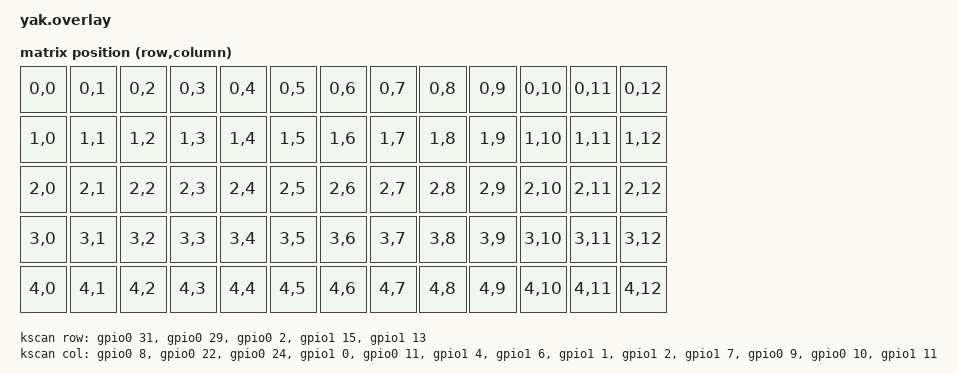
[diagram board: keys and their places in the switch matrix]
// This file was generated from a template. Edit it to match your keyboard.
// See https://zmk.dev/docs/development/hardware-integration/new-shield for more
// instructions.

#include <dt-bindings/zmk/matrix_transform.h>

#include "yak-layouts.dtsi"

&pinctrl {
    spi0_default: spi0_default {
        group1 {
            psels = <NRF_PSEL(SPIM_SCK, 0, 20)>,
                <NRF_PSEL(SPIM_MOSI, 0, 17)>,
                <NRF_PSEL(SPIM_MISO, 0, 25)>;
        };
    };
    spi0_sleep: spi0_sleep {
        group1 {
            psels = <NRF_PSEL(SPIM_SCK, 0, 20)>,
                <NRF_PSEL(SPIM_MOSI, 0, 17)>,
                <NRF_PSEL(SPIM_MISO, 0, 25)>;
            low-power-enable;
        };
    };
};

nice_view_spi: &spi0 {
    compatible = "nordic,nrf-spim";
    pinctrl-0 = <&spi0_default>;
    pinctrl-1 = <&spi0_sleep>;
    pinctrl-names = "default", "sleep";
    cs-gpios = <&pro_micro 6 GPIO_ACTIVE_HIGH>;
};

/ {
    chosen {
        zmk,physical-layout = &default_layout;
    };

    kscan: kscan {
        compatible = "zmk,kscan-gpio-matrix";
        diode-direction = "col2row";
        wakeup-source;

        // Replace these comments with the GPIO pins in the matrix.
        // See https://zmk.dev/docs/development/hardware-integration/new-shield#shield-overlays
        col-gpios
            = <&gpio0 8 GPIO_ACTIVE_HIGH>  /* COL1 -> P0.08 */
            , <&gpio0 22 GPIO_ACTIVE_HIGH>  /* COL2 -> P0.22 */
            , <&gpio0 24 GPIO_ACTIVE_HIGH>  /* COL3 -> P0.24 */
            , <&gpio1 0 GPIO_ACTIVE_HIGH>  /* COL4 -> P1.00 */
            , <&gpio0 11 GPIO_ACTIVE_HIGH>  /* COL5 -> P0.11 */
            , <&gpio1 4 GPIO_ACTIVE_HIGH>  /* COL6 -> P1.04 */
            , <&gpio1 6 GPIO_ACTIVE_HIGH>  /* COL7 -> P1.06 */
            , <&gpio1 1 GPIO_ACTIVE_HIGH>  /* COL8 -> P1.01 */
            , <&gpio1 2 GPIO_ACTIVE_HIGH>  /* COL9 -> P1.02 */
            , <&gpio1 7 GPIO_ACTIVE_HIGH>  /* COL10 -> P1.07 */
            , <&gpio0 9 GPIO_ACTIVE_HIGH>  /* COL11 -> P0.09 */
            , <&gpio0 10 GPIO_ACTIVE_HIGH>  /* COL12 -> P0.10 */
            , <&gpio1 11 GPIO_ACTIVE_HIGH>  /* COL13 -> P1.11 */
            ;

        row-gpios
            = <&gpio0 31 (GPIO_ACTIVE_HIGH | GPIO_PULL_DOWN)>  /* ROW1 -> P0.31 */
            , <&gpio0 29 (GPIO_ACTIVE_HIGH | GPIO_PULL_DOWN)>  /* ROW2 -> P0.29 */
            , <&gpio0 2 (GPIO_ACTIVE_HIGH | GPIO_PULL_DOWN)>  /* ROW3 -> P0.02 */
            , <&gpio1 15 (GPIO_ACTIVE_HIGH | GPIO_PULL_DOWN)>  /* ROW4 -> P1.15 */
            , <&gpio1 13 (GPIO_ACTIVE_HIGH | GPIO_PULL_DOWN)>  /* ROW5 -> P1.13 */
            ;
    };

    default_transform: default_transform {
        compatible = "zmk,matrix-transform";
        columns = <13>;
        rows = <5>;

        map = <
            RC(0, 0) RC(0, 1) RC(0, 2) RC(0, 3) RC(0, 4) RC(0, 5) RC(0, 6) RC(0, 7) RC(0, 8) RC(0, 9) RC(0, 10) RC(0, 11) RC(0, 12)
            RC(1, 0) RC(1, 1) RC(1, 2) RC(1, 3) RC(1, 4) RC(1, 5) RC(1, 6) RC(1, 7) RC(1, 8) RC(1, 9) RC(1, 10) RC(1, 11) RC(1, 12)
            RC(2, 0) RC(2, 1) RC(2, 2) RC(2, 3) RC(2, 4) RC(2, 5) RC(2, 6) RC(2, 7) RC(2, 8) RC(2, 9) RC(2, 10) RC(2, 11) RC(2, 12)
            RC(3, 0) RC(3, 1) RC(3, 2) RC(3, 3) RC(3, 4) RC(3, 5) RC(3, 6) RC(3, 7) RC(3, 8) RC(3, 9) RC(3, 10) RC(3, 11) RC(3, 12)
            RC(4, 0) RC(4, 1) RC(4, 2) RC(4, 3) RC(4, 4) RC(4, 5) RC(4, 6) RC(4, 7) RC(4, 8) RC(4, 9) RC(4, 10) RC(4, 11) RC(4, 12)
        >;
    };
};
